# ATmega8515 device description
Architecture: AVR8; Family: megaAVR
Registers are 8-bit, access not given, no defined reset value unless marked. A register's access mark holds for its fields unless they carry their own. Offsets are from the block's base; [hi:lo] are bit positions; 'fields as' and 'values as' point back to an identical list.

## USART
Instances: USART 0x00
0x29 UBRRL — USART Baud Rate Register Low Byte
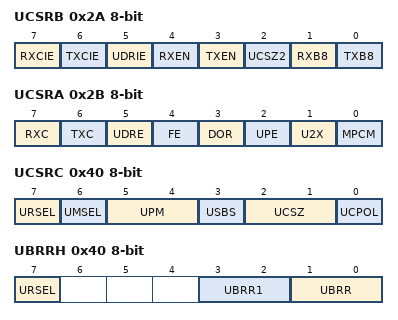
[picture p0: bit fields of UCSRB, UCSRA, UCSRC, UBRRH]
0x2A UCSRB — USART Control and Status Register B
  [7] RXCIE — RX Complete Interrupt Enable
  [6] TXCIE — TX Complete Interrupt Enable
  [5] UDRIE — USART Data register Empty Interrupt Enable
  [4] RXEN — Receiver Enable
  [3] TXEN — Transmitter Enable
  [2] UCSZ2 — Character Size Bit 2
  [1] RXB8 — Receive Data Bit 8
  [0] TXB8 — Transmit Data Bit 8
0x2B UCSRA — USART Control and Status Register A
  [7] RXC — USART Receive Complete
  [6] TXC — USART Transmitt Complete
  [5] UDRE — USART Data Register Empty
  [4] FE — Framing Error
  [3] DOR — Data overRun
  [2] UPE — Parity Error
  [1] U2X — Double the USART transmission speed
  [0] MPCM — Multi-processor Communication Mode
0x2C UDR — USART I/O Data Register
0x40 UCSRC — USART Control and Status Register C
  [7] URSEL — Register Select
  [6] UMSEL — USART Mode Select
    0=Asynchronous Operation; 1=Synchronous Operation
  [5:4] UPM — Parity Mode Bits
    0=Disabled; 2=Enabled, Even Parity; 3=Enabled, Odd Parity
  [3] USBS — Stop Bit Select
    0=1-bit; 1=2-bit
  [2:1] UCSZ — Character Size Bits
  [0] UCPOL — Clock Polarity
0x40 UBRRH — USART Baud Rate Register High Byte
  [7] URSEL — Register Select
  [3:2] UBRR1 — USART Baud Rate Register bit 11
  [1:0] UBRR (bit 8 of the value upward) — USART Baud Rate Register bits

## SPI — Serial Peripheral Interface
Instances: SPI 0x00
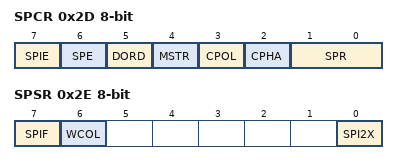
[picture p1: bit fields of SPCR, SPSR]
0x2D SPCR — SPI Control Register
  [7] SPIE — SPI Interrupt Enable
  [6] SPE — SPI Enable
  [5] DORD — Data Order
  [4] MSTR — Master/Slave Select
  [3] CPOL — Clock polarity
  [2] CPHA — Clock Phase
  [1:0] SPR — SPI Clock Rate Selects
    0=fosc/4; 1=fosc/16; 2=fosc/64; 3=fosc/128; 4=fosc/2; 5=fosc/8; 6=fosc/32; 7=fosc/64
0x2E SPSR — SPI Status Register
  [7] SPIF — SPI Interrupt Flag
  [6] WCOL — Write Collision Flag
  [0] SPI2X — Double SPI Speed Bit
0x2F SPDR — SPI Data Register

## CPU — CPU Registers
Instances: CPU 0x00
Parameters: CORE_VERSION=V2E
0x24 OSCCAL — Oscillator Calibration Value
  [7:0] OSCCAL — Oscillator Calibration
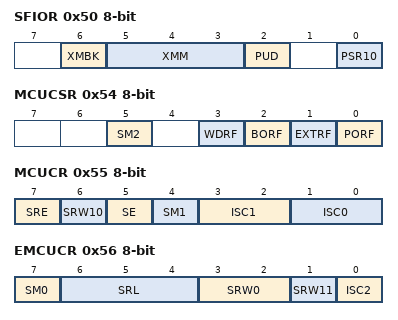
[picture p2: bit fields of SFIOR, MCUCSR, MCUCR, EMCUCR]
0x50 SFIOR — Special Function IO Register
  [6] XMBK — External Memory Bus Keeper Enable
  [5:3] XMM — External Memory High Mask Bits
  [2] PUD — Pull-up Disable
  [0] PSR10 — Prescaler Reset Timer / Counter 1 and Timer / Counter 0
0x54 MCUCSR — MCU Control And Status Register
  [5] SM2 — Sleep Mode Select Bit 2
  [3] WDRF — Watchdog Reset Flag
  [2] BORF — Brown-out Reset Flag
  [1] EXTRF — External Reset Flag
  [0] PORF — Power-on reset flag
0x55 MCUCR — MCU Control Register
  [7] SRE — External SRAM/XMEM Enable
  [6] SRW10 — Wait State Select Bits for Upper Sector, bit 0
  [5] SE — Sleep Enable
  [4] SM1 — Sleep Mode Select Bit 1
  [3:2] ISC1 — Interrupt Sense Control 1 Bits
    0=Low Level of INTX; 1=Any Logical Change in INTX; 2=Falling Edge of INTX; 3=Rising Edge of INTX
  [1:0] ISC0 — Interrupt Sense Control 0 Bits
    values as ISC1
0x56 EMCUCR — Extended MCU Control Register
  [7] SM0 — Sleep Mode Select Bit 0
  [6:4] SRL — Wait State Selector Limit bits
    0=LS = N/A, US = 0x1100 - 0xFFFF; 1=LS = 0x1100 - 0x1FFF, US = 0x2000 - 0xFFFF; 2=LS = 0x1100 - 0x3FFF, US = 0x4000 - 0xFFFF; 3=LS = 0x1100 - 0x5FFF, US = 0x6000 - 0xFFFF; 4=LS = 0x1100 - 0x7FFF, US = 0x8000 - 0xFFFF; 5=LS = 0x1100 - 0x9FFF, US = 0xA000 - 0xFFFF; 6=LS = 0x1100 - 0xBFFF, US = 0xC000 - 0xFFFF; 7=LS = 0x1100 - 0xDFFF, US = 0xE000 - 0xFFFF
  [3:2] SRW0 — Wait State Select Bits for Lower Sector, bits
    0=No wait-states; 1=Wait one cycle during read/write strobe; 2=Wait two cycles during read/write strobe; 3=Wait two cycles during read/write and wait one cycle before driving out new address
  [1] SRW11 — Wait State Select Bits for Upper Sector, bit 1
  [0] ISC2 — Interrupt Sense Control 2
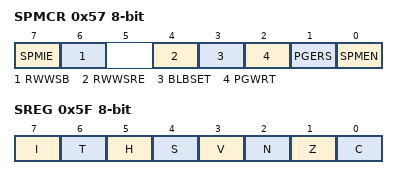
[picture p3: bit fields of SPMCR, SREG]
0x57 SPMCR — Store Program Memory Control Register
  [7] SPMIE — SPM Interrupt Enable
  [6] RWWSB — Read-While-Write Section Busy
  [4] RWWSRE — Read-While-Write Section Read Enable
  [3] BLBSET — Boot Lock Bit Set
  [2] PGWRT — Page Write
  [1] PGERS — Page Erase
  [0] SPMEN — Store Program Memory Enable
0x5D SP 16-bit — Stack Pointer
0x5F SREG — Status Register
  [7] I — Global Interrupt Enable
  [6] T — Bit Copy Storage
  [5] H — Half Carry Flag
  [4] S — Sign Bit
  [3] V — Two's Complement Overflow Flag
  [2] N — Negative Flag
  [1] Z — Zero Flag
  [0] C — Carry Flag
Value list OSCCAL_VALUE_ADDRESSES: 0=1_Mhz; 1=2_Mhz; 2=4_Mhz; 3=8_Mhz
